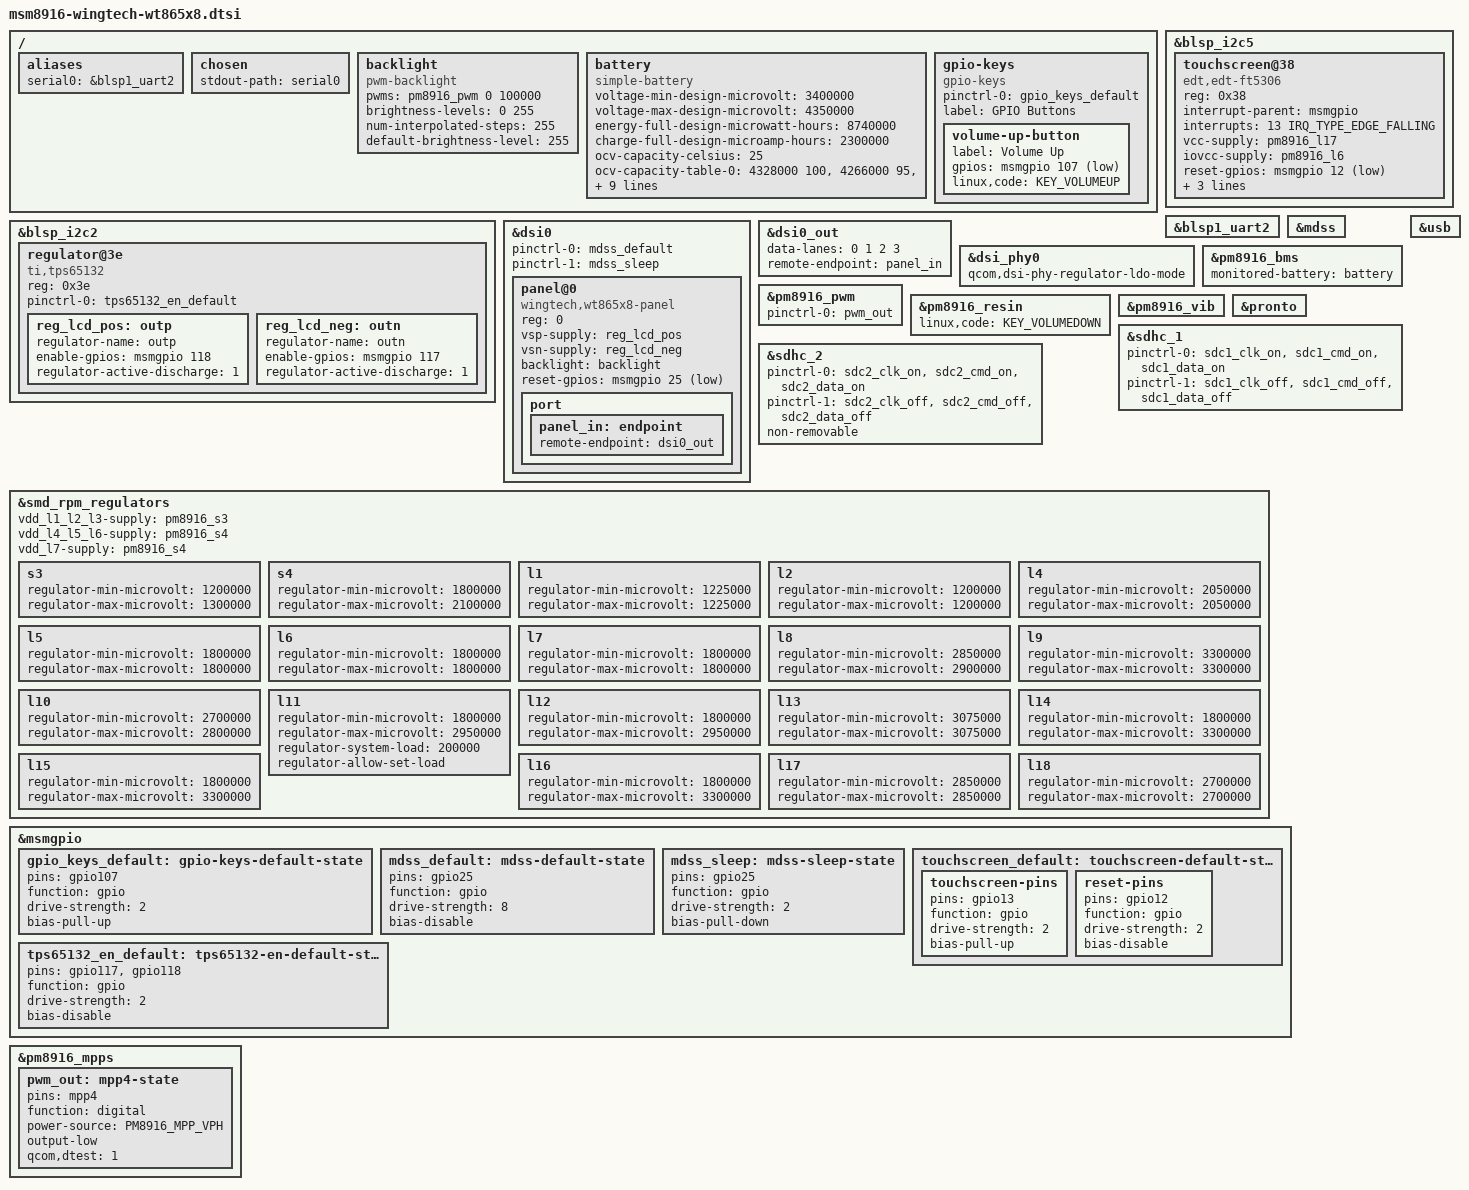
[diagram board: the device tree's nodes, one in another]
// SPDX-License-Identifier: GPL-2.0-only

#include "msm8916-pm8916.dtsi"
#include <dt-bindings/gpio/gpio.h>
#include <dt-bindings/pinctrl/qcom,pmic-mpp.h>

/ {
	aliases {
		serial0 = &blsp1_uart2;
	};

	chosen {
		stdout-path = "serial0";
	};

	backlight: backlight {
		compatible = "pwm-backlight";
		pwms = <&pm8916_pwm 0 100000>;

		brightness-levels = <0 255>;
		num-interpolated-steps = <255>;
		default-brightness-level = <255>;
	};

	battery: battery {
		compatible = "simple-battery";
		voltage-min-design-microvolt = <3400000>;
		voltage-max-design-microvolt = <4350000>;
		energy-full-design-microwatt-hours = <8740000>;
		charge-full-design-microamp-hours = <2300000>;

		ocv-capacity-celsius = <25>;
		ocv-capacity-table-0 = <4328000 100>, <4266000 95>, <4208000 90>,
			<4154000 85>, <4102000 80>, <4062000 75>, <3992000 70>,
			<3960000 65>, <3914000 60>, <3870000 55>, <3840000 50>,
			<3818000 45>, <3800000 40>, <3784000 35>, <3770000 30>,
			<3756000 25>, <3736000 20>, <3714000 16>, <3696000 13>,
			<3690000 11>, <3689000 10>, <3688000 9>, <3686000 8>,
			<3682000 7>, <3670000 6>, <3639000 5>, <3592000 4>,
			<3530000 3>, <3448000 2>, <3320000 1>, <3000000 0>;
	};

	gpio-keys {
		compatible = "gpio-keys";

		pinctrl-0 = <&gpio_keys_default>;
		pinctrl-names = "default";

		label = "GPIO Buttons";

		volume-up-button {
			label = "Volume Up";
			gpios = <&msmgpio 107 GPIO_ACTIVE_LOW>;
			linux,code = <KEY_VOLUMEUP>;
		};
	};
};

&blsp_i2c2 {
	status = "okay";

	regulator@3e {
		compatible = "ti,tps65132";
		reg = <0x3e>;

		pinctrl-0 = <&tps65132_en_default>;
		pinctrl-names = "default";

		reg_lcd_pos: outp {
			regulator-name = "outp";
			enable-gpios = <&msmgpio 118 GPIO_ACTIVE_HIGH>;
			regulator-active-discharge = <1>;
		};

		reg_lcd_neg: outn {
			regulator-name = "outn";
			enable-gpios = <&msmgpio 117 GPIO_ACTIVE_HIGH>;
			regulator-active-discharge = <1>;
		};
	};
};

&blsp_i2c5 {
	status = "okay";

	touchscreen@38 {
		/* actually FT5336 */
		compatible = "edt,edt-ft5306";
		reg = <0x38>;

		interrupt-parent = <&msmgpio>;
		interrupts = <13 IRQ_TYPE_EDGE_FALLING>;

		vcc-supply = <&pm8916_l17>;
		iovcc-supply = <&pm8916_l6>;

		reset-gpios = <&msmgpio 12 GPIO_ACTIVE_LOW>;

		touchscreen-size-x = <720>;
		touchscreen-size-y = <1280>;

		pinctrl-0 = <&touchscreen_default>;
		pinctrl-names = "default";
	};
};

&blsp1_uart2 {
	status = "okay";
};

&dsi0 {
	pinctrl-0 = <&mdss_default>;
	pinctrl-1 = <&mdss_sleep>;
	pinctrl-names = "default", "sleep";

	panel@0 {
		compatible = "wingtech,wt865x8-panel";
		reg = <0>;

		vsp-supply = <&reg_lcd_pos>;
		vsn-supply = <&reg_lcd_neg>;

		backlight = <&backlight>;
		reset-gpios = <&msmgpio 25 GPIO_ACTIVE_LOW>;

		port {
			panel_in: endpoint {
				remote-endpoint = <&dsi0_out>;
			};
		};
	};
};

&dsi0_out {
	data-lanes = <0 1 2 3>;
	remote-endpoint = <&panel_in>;
};

&dsi_phy0 {
	qcom,dsi-phy-regulator-ldo-mode;
};

&mdss {
	status = "okay";
};

&pm8916_bms {
	monitored-battery = <&battery>;
	status = "okay";
};

&pm8916_pwm {
	pinctrl-0 = <&pwm_out>;
	pinctrl-names = "default";
	status = "okay";
};

&pm8916_resin {
	linux,code = <KEY_VOLUMEDOWN>;
	status = "okay";
};

&pm8916_vib {
	status = "okay";
};

&pronto {
	status = "okay";
};

&sdhc_1 {
	pinctrl-0 = <&sdc1_clk_on &sdc1_cmd_on &sdc1_data_on>;
	pinctrl-1 = <&sdc1_clk_off &sdc1_cmd_off &sdc1_data_off>;
	pinctrl-names = "default", "sleep";

	status = "okay";
};

&sdhc_2 {
	pinctrl-0 = <&sdc2_clk_on &sdc2_cmd_on &sdc2_data_on>;
	pinctrl-1 = <&sdc2_clk_off &sdc2_cmd_off &sdc2_data_off>;
	pinctrl-names = "default", "sleep";

	non-removable;

	status = "okay";
};

&usb {
	status = "okay";
};

&smd_rpm_regulators {
	vdd_l1_l2_l3-supply = <&pm8916_s3>;
	vdd_l4_l5_l6-supply = <&pm8916_s4>;
	vdd_l7-supply = <&pm8916_s4>;

	s3 {
		regulator-min-microvolt = <1200000>;
		regulator-max-microvolt = <1300000>;
	};

	s4 {
		regulator-min-microvolt = <1800000>;
		regulator-max-microvolt = <2100000>;
	};

	l1 {
		regulator-min-microvolt = <1225000>;
		regulator-max-microvolt = <1225000>;
	};

	l2 {
		regulator-min-microvolt = <1200000>;
		regulator-max-microvolt = <1200000>;
	};

	l4 {
		regulator-min-microvolt = <2050000>;
		regulator-max-microvolt = <2050000>;
	};

	l5 {
		regulator-min-microvolt = <1800000>;
		regulator-max-microvolt = <1800000>;
	};

	l6 {
		regulator-min-microvolt = <1800000>;
		regulator-max-microvolt = <1800000>;
	};

	l7 {
		regulator-min-microvolt = <1800000>;
		regulator-max-microvolt = <1800000>;
	};

	l8 {
		regulator-min-microvolt = <2850000>;
		regulator-max-microvolt = <2900000>;
	};

	l9 {
		regulator-min-microvolt = <3300000>;
		regulator-max-microvolt = <3300000>;
	};

	l10 {
		regulator-min-microvolt = <2700000>;
		regulator-max-microvolt = <2800000>;
	};

	l11 {
		regulator-min-microvolt = <1800000>;
		regulator-max-microvolt = <2950000>;
		regulator-system-load = <200000>;
		regulator-allow-set-load;
	};

	l12 {
		regulator-min-microvolt = <1800000>;
		regulator-max-microvolt = <2950000>;
	};

	l13 {
		regulator-min-microvolt = <3075000>;
		regulator-max-microvolt = <3075000>;
	};

	l14 {
		regulator-min-microvolt = <1800000>;
		regulator-max-microvolt = <3300000>;
	};

	l15 {
		regulator-min-microvolt = <1800000>;
		regulator-max-microvolt = <3300000>;
	};

	l16 {
		regulator-min-microvolt = <1800000>;
		regulator-max-microvolt = <3300000>;
	};

	l17 {
		regulator-min-microvolt = <2850000>;
		regulator-max-microvolt = <2850000>;
	};

	l18 {
		regulator-min-microvolt = <2700000>;
		regulator-max-microvolt = <2700000>;
	};
};

&msmgpio {
	gpio_keys_default: gpio-keys-default-state {
		pins = "gpio107";
		function = "gpio";
		drive-strength = <2>;
		bias-pull-up;
	};

	mdss_default: mdss-default-state {
		pins = "gpio25";
		function = "gpio";
		drive-strength = <8>;
		bias-disable;
	};

	mdss_sleep: mdss-sleep-state {
		pins = "gpio25";
		function = "gpio";
		drive-strength = <2>;
		bias-pull-down;
	};

	touchscreen_default: touchscreen-default-state {
		touchscreen-pins {
			pins = "gpio13";
			function = "gpio";
			drive-strength = <2>;
			bias-pull-up;
		};

		reset-pins {
			pins = "gpio12";
			function = "gpio";
			drive-strength = <2>;
			bias-disable;
		};
	};

	tps65132_en_default: tps65132-en-default-state {
		pins = "gpio117", "gpio118";
		function = "gpio";
		drive-strength = <2>;
		bias-disable;
	};
};

&pm8916_mpps {
	pwm_out: mpp4-state {
		pins = "mpp4";
		function = "digital";
		power-source = <PM8916_MPP_VPH>;
		output-low;
		qcom,dtest = <1>;
	};
};
